# STM32U535xx register map
File version: 1.0
Registers are 32-bit, read-write, reset 0x0 unless marked. A register's access mark holds for its fields unless they carry their own. Offsets are from the block's base; [hi:lo] are bit positions; {n}, {i} and the like mark numbered series.

## HASH
Base 0x420C0400
Same registers: HASH_S 0x520C0400
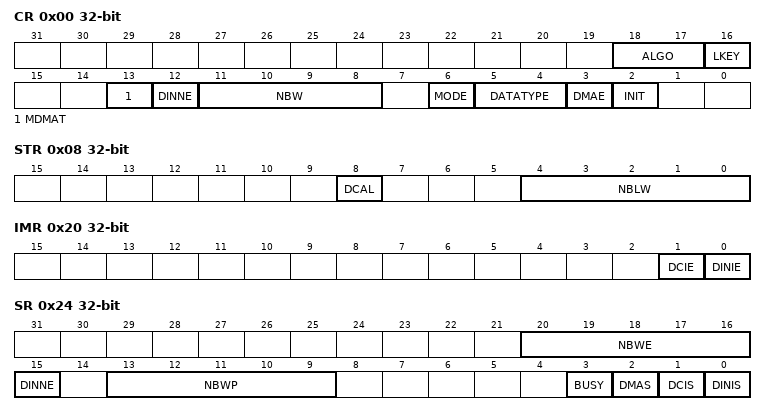
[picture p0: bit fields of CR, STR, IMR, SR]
0x00 CR — HASH control register
  [18:17] ALGO, [16] LKEY, [13] MDMAT, [12] DINNE, [11:8] NBW, [6] MODE, [5:4] DATATYPE, [3] DMAE, [2] INIT
0x04 DIN — HASH data input register
0x08 STR — HASH start register
  [8] DCAL, [4:0] NBLW
{0xC+4i} HR{i} (i=0..4) — HASH digest registers
0x20 IMR — HASH interrupt enable register
  [1] DCIE, [0] DINIE
0x24 SR — HASH status register
  [20:16] NBWE, [15] DINNE, [13:9] NBWP, [3] BUSY, [2] DMAS, [1] DCIS, [0] DINIS
{0xF8+4i} CSR{i} (i=0..53) — HASH context swap registers
{0x310+4i} DIGEST_HR{i} (i=0..7) — HASH digest registers

## RNG
Base 0x420C0800
Same registers: RNG_S 0x520C0800
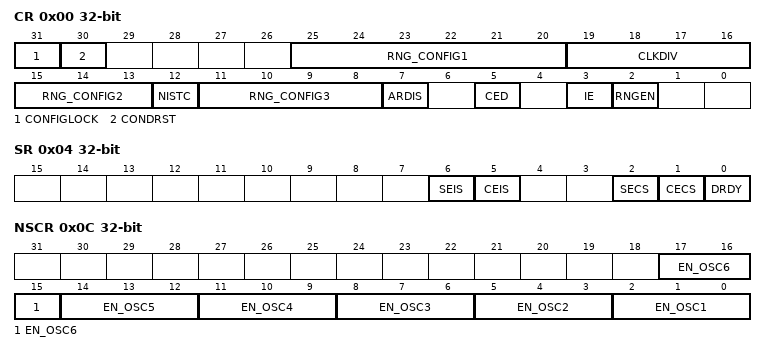
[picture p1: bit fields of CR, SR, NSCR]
0x00 CR — RNG control register
  [31] CONFIGLOCK
  [30] CONDRST
  [25:20] RNG_CONFIG1
  [19:16] CLKDIV
    0=BY_1 (No clock division); 1=BY_2 (2 RNG clock cycles per internal RNG clock); 2=BY_4 (4 RNG clock cycles per internal RNG clock); 3=BY_8 (8 RNG clock cycles per internal RNG clock); 4=BY_16 (16 RNG clock cycles per internal RNG clock); 5=BY_32 (32 RNG clock cycles per internal RNG clock); 6=BY_64 (64 RNG clock cycles per internal RNG clock); 7=BY_128 (128 RNG clock cycles per internal RNG clock); 8=BY_256 (256 RNG clock cycles per internal RNG clock); 9=BY_512 (512 RNG clock cycles per internal RNG clock); 10=BY_1024 (1024 RNG clock cycles per internal RNG clock); 11=BY_2048 (2048 RNG clock cycles per internal RNG clock); 12=BY_4096 (4096 RNG clock cycles per internal RNG clock); 13=BY_8192 (8192 RNG clock cycles per internal RNG clock); 14=BY_16384 (16384 RNG clock cycles per internal RNG clock); 15=BY_32768 (32768 RNG clock cycles per internal RNG clock)
  [15:13] RNG_CONFIG2
  [12] NISTC
  [11:8] RNG_CONFIG3
  [7] ARDIS
  [5] CED
  [3] IE
  [2] RNGEN
0x04 SR — RNG status register
  [6] SEIS, [5] CEIS, [2] SECS, [1] CECS, [0] DRDY
0x08 DR — RNG data register
0x0C NSCR — RNG noise source control register
  [3n-1:3n-3] EN_OSC{n} (n=1..6)
0x10 HTCR — RNG health test configuration register
  [31:0] HTCFG

## DLYB_SDMMC1 — Delay Block DLYB
Base 0x420C8400
Same registers: DLYB_OCTOSPI1 0x420CF000, DLYB_SDMMC1_S 0x520C8400, DLYB_OCTOSPI1_S 0x520CF000
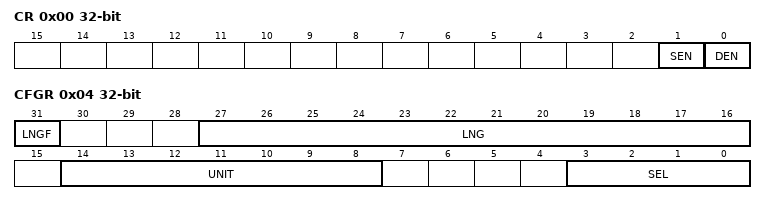
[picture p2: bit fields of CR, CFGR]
0x00 CR — DELAY BLOCK control register
  [1] SEN — Sampler length enable
  [0] DEN — Delay Block enable
0x04 CFGR — DELAY BLOCK configuration register
  [31] LNGF — Length valid flag
  [27:16] LNG — Delay line length value[11:0]
  [14:8] UNIT — Delay Defines the delay of a Unit delay cell[6:0]
  [3:0] SEL — Select the phase for the Output clock[3:0]

## SYSCFG — System configuration controller
Base 0x46000400
Same registers: SYSCFG_S 0x56000400
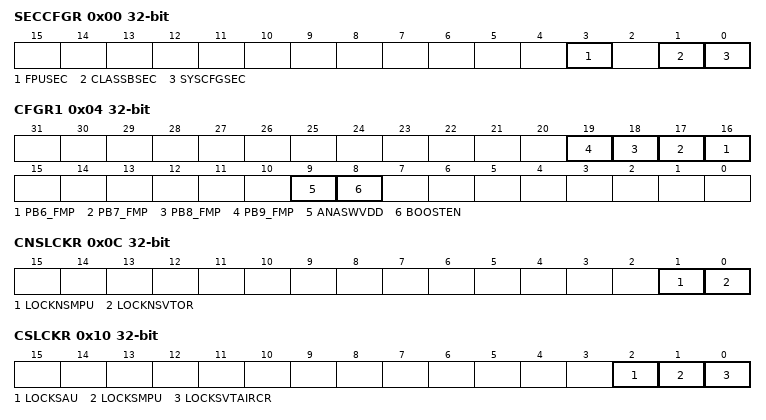
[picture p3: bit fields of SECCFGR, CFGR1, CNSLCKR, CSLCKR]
0x00 SECCFGR — SYSCFG secure configuration register
  [3] FPUSEC — FPU SYSCFG security enable
  [1] CLASSBSEC — ClassB SYSCFG security enable
  [0] SYSCFGSEC — SYSCFG clock control security enable
0x04 CFGR1 — SYSCFG configuration register 1
  [n+10] PB{n}_FMP (n=6..9) — PB{n} Fast mode plus
  [9] ANASWVDD — GPIO analog switch control voltage selection
  [8] BOOSTEN — I/O analog switch voltage booster enable
0x08 FPUIMR — SYSCFG FPU interrupt mask register
  [5:0] FPU_IE — All FPU interrupts enable
0x0C CNSLCKR — SYSCFG CPU non-secure lock register
  [1] LOCKNSMPU — Disable Non-Secure MPU registers writes by SW or debug agent
  [0] LOCKNSVTOR — Disable VTOR_NS register writes by SW or debug agent
0x10 CSLCKR — SYSCFG CPU secure lock register
  [2] LOCKSAU — Disable changes to SAU registers
  [1] LOCKSMPU — Disable changes to the secure MPU registers writes by SW or debug agent
  [0] LOCKSVTAIRCR — Disable changes to the secure vector table address, handling of system faults
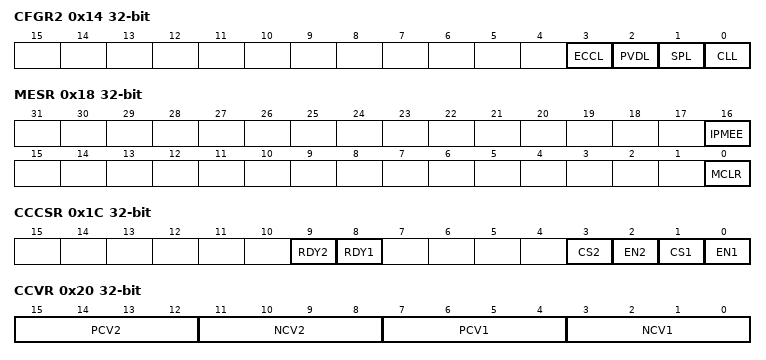
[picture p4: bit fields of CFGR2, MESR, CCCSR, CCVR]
0x14 CFGR2 — SYSCFG configuration register 2
  [3] ECCL — ECC Lock
  [2] PVDL — PVD Lock
  [1] SPL — SRAM ECC Lock
  [0] CLL — Core Lockup Lock
0x18 MESR — SYSCFG Memory Erase Status register
  [16] IPMEE — Status of End of Erase for ICache and PKA RAMs
  [0] MCLR — Status of Erase after Reset
0x1C CCCSR — SYSCFG Conpensaion Cell Control&Status register
  [9] RDY2 — VDDIO compensation cell ready flag
  [8] RDY1 — VDD compensation cell ready flag
  [3] CS2 — Code selection for VDDIO power rail
  [2] EN2 — Enable compensation cell for VDDIO power rail
  [1] CS1 — Code selection for VDD power rail
  [0] EN1 — Enable compensation cell for VDD power rail
0x20 CCVR — SYSCFG Conpensaion Cell value register
  [15:12] PCV2 — PMOS compensation value for VDDIO Power Rail
  [11:8] NCV2 — NMOS compensation value for VDDIO Power Rail
  [7:4] PCV1 — PMOS compensation value for VDD Power Rail
  [3:0] NCV1 — NMOS compensation value for VDD Power Rail
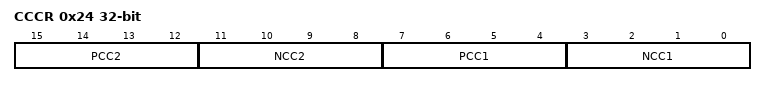
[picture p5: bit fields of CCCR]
0x24 CCCR — SYSCFG Conpensaion Cell Code register
  [15:12] PCC2 — PMOS compensation code for VDDIO Power Rail
  [11:8] NCC2 — NMOS compensation code for VDDIO Power Rail
  [7:4] PCC1 — PMOS compensation code for VDD Power Rail
  [3:0] NCC1 — NMOS compensation code for VDD Power Rail
0x2C RSSCMDR — SYSCFG RSS command mode register
  [15:0] RSSCMD — RSS command
